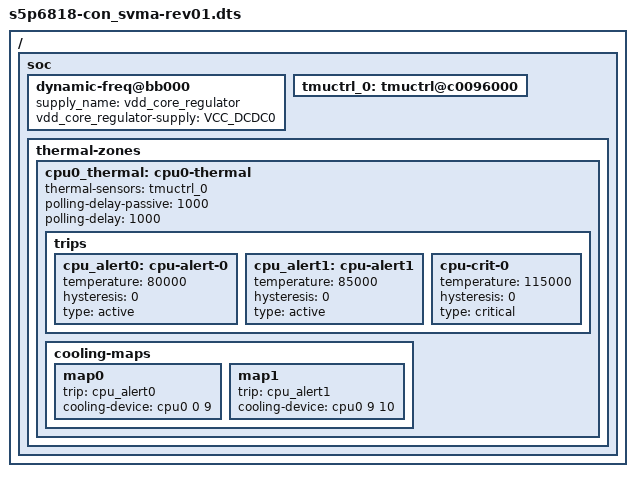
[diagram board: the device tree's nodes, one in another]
/*
 * Copyright (C) 2019  Nexell Co., Ltd.
 * Author: Sungwoo, Park <swpark@nexell.co.kr>
 *
 * This program is free software; you can redistribute it and/or
 * modify it under the terms of the GNU General Public License
 * as published by the Free Software Foundation; either version 2
 * of the License, or (at your option) any later version.
 *
 * This program is distributed in the hope that it will be useful,
 * but WITHOUT ANY WARRANTY; without even the implied warranty of
 * MERCHANTABILITY or FITNESS FOR A PARTICULAR PURPOSE.  See the
 * GNU General Public License for more details.
 *
 * You should have received a copy of the GNU General Public License
 * along with this program.  If not, see <http://www.gnu.org/licenses/>.
 */

/dts-v1/;
#include "s5p6818-con_svma-common.dtsi"

/ {
	soc {
		dynamic-freq@bb000 {
			supply_name = "vdd_core_regulator";
			vdd_core_regulator-supply = <&VCC_DCDC0>;
		};

		tmuctrl_0: tmuctrl@c0096000 {
			status = "okay";
		};

		thermal-zones {
			cpu0_thermal: cpu0-thermal {
				thermal-sensors = <&tmuctrl_0>;
				polling-delay-passive = <1000>;
				polling-delay = <1000>;
				trips {
					cpu_alert0: cpu-alert-0 {
						temperature = <80000>;
						hysteresis = <0>;
						type = "active";
					};
					cpu_alert1: cpu-alert1 {
						temperature = <85000>;
						hysteresis = <0>;
						type = "active";
					};
					cpu-crit-0 {
						temperature = <115000>;
						hysteresis = <0>;
						type = "critical";
					};
				};
				cooling-maps {
					map0 {
						trip = <&cpu_alert0>;
						cooling-device = <&cpu0 0 9>;
					};
					map1 {
						trip = <&cpu_alert1>;
						cooling-device = <&cpu0 9 10>;
					};
				};
			};
		};
	};
};
